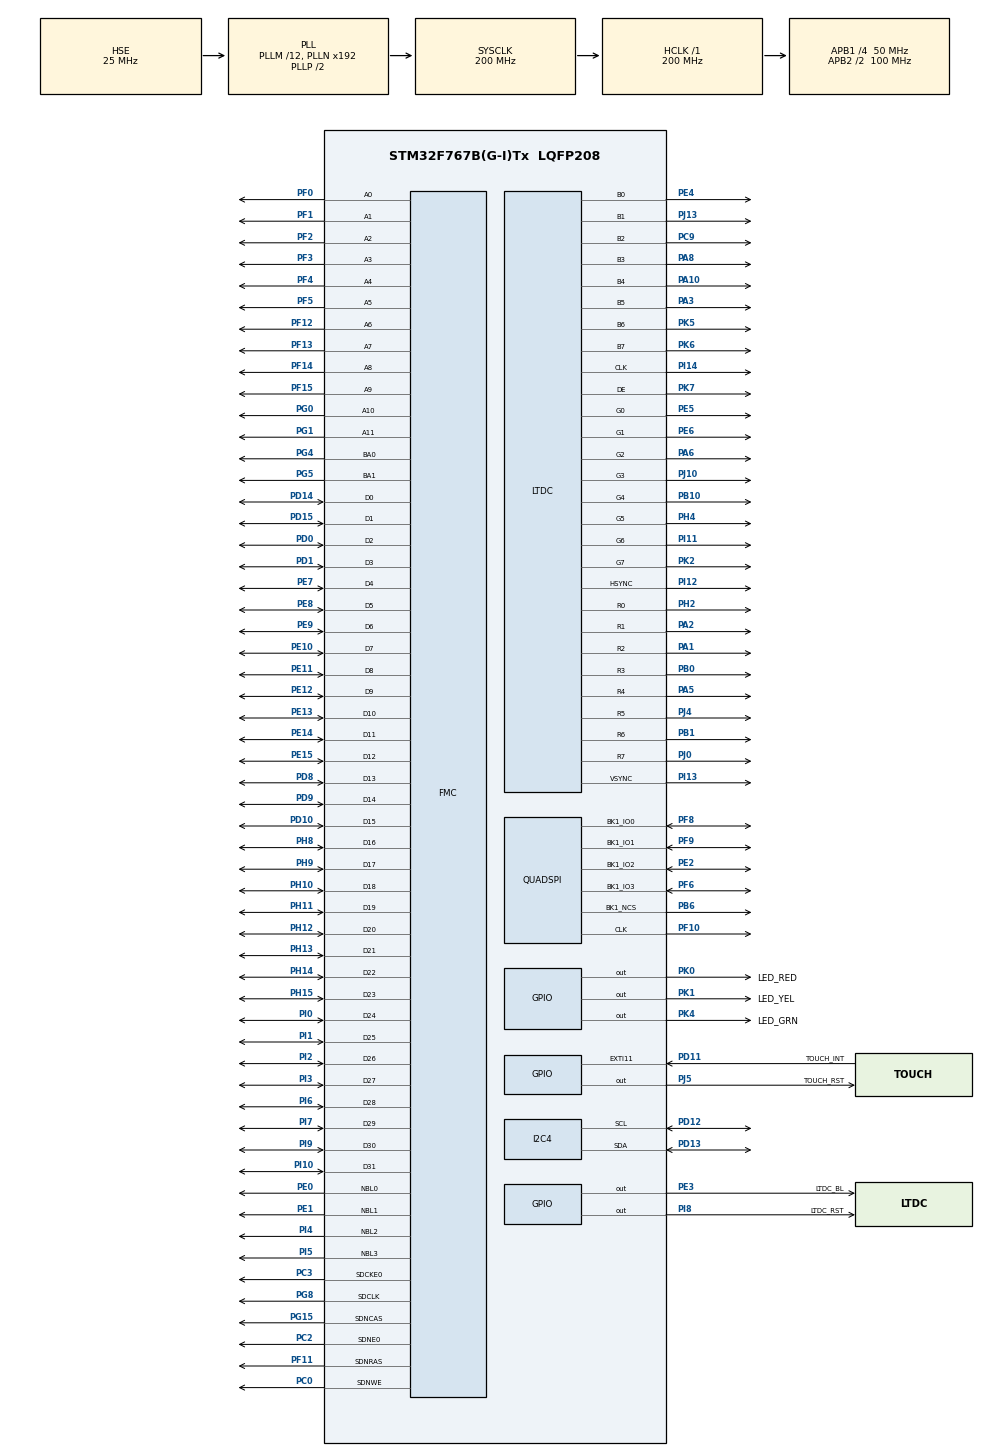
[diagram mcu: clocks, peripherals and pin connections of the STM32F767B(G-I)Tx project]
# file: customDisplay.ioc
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CORTEX_M7.ART_ACCELERATOR_ENABLE=1
DMA2D.ColorMode=DMA2D_OUTPUT_RGB888
FMC.CASLatency1=FMC_SDRAM_CAS_LATENCY_3
FMC.ColumnBitsNumber1=FMC_SDRAM_COLUMN_BITS_NUM_8
FMC.ExitSelfRefreshDelay1=7
FMC.LoadToActiveDelay1=2
FMC.RCDDelay1=3
FMC.RPDelay1=3
FMC.ReadBurst1=FMC_SDRAM_RBURST_ENABLE
FMC.RowCycleDelay1=10
FMC.SDClockPeriod1=FMC_SDRAM_CLOCK_PERIOD_2
FMC.SelfRefreshTime1=7
FMC.WriteRecoveryTime1=6
FREERTOS.Mutexes01=mutexLCD,Dynamic,NULL;mutexSDRAM,Dynamic,NULL;mutexFLASH,Dynamic,NULL;mutexTOUCH,Dynamic,NULL
FREERTOS.Tasks01=heartbeatTask,1,128,execHeartbeatTask,Default,NULL,Dynamic,NULL,NULL;lcdTestTask,-1,1024,execLcdTestTask,Default,NULL,Dynamic,NULL,NULL;sdramTestTask,-1,1024,execSdramTestTask,Default,NULL,Dynamic,NULL,NULL;flashTestTask,-1,1024,execFlashTestTask,Default,NULL,Dynamic,NULL,NULL;touchTestTask,-1,512,execTouchTestTask,Default,NULL,Dynamic,NULL,NULL;touchgfxTask,-2,8192,execTouchgfxTask,Default,NULL,Dynamic,NULL,NULL
FREERTOS.configGENERATE_RUN_TIME_STATS=1
FREERTOS.configTOTAL_HEAP_SIZE=65536
FREERTOS.configUSE_NEWLIB_REENTRANT=1
FREERTOS.configUSE_STATS_FORMATTING_FUNCTIONS=1
FREERTOS.configUSE_TRACE_FACILITY=1
I2C4.Timing=0x00C0EAFF
LTDC.ActiveH=272
LTDC.ActiveW=480
LTDC.Alpha_L0=255
LTDC.FBStartAdress_L0=0xC0000000
LTDC.HBP=43
LTDC.HFP=8
LTDC.HSync=1
LTDC.ImageHeight_L0=272
LTDC.ImageWidth_L0=480
LTDC.Layers=0
LTDC.PixelFormat_L0=LTDC_PIXEL_FORMAT_RGB888
LTDC.VBP=12
LTDC.VFP=4
LTDC.VSync=10
LTDC.WindowX1_L0=480
LTDC.WindowY1_L0=272
Mcu.Family=STM32F7
Mcu.Name=STM32F767B(G-I)Tx
Mcu.Package=LQFP208
NVIC.DMA2D_IRQn=true\:5\:0\:false\:false\:true\:true\:true\:true
NVIC.LTDC_IRQn=true\:5\:0\:false\:false\:true\:true\:true\:true
NVIC.PriorityGroup=NVIC_PRIORITYGROUP_4
NVIC.TIM8_TRG_COM_TIM14_IRQn=true\:15\:0\:false\:false\:true\:false\:false\:true
NVIC.TimeBase=TIM8_TRG_COM_TIM14_IRQn
NVIC.TimeBaseIP=TIM14
PA1.Mode=RGB888
PA1.Signal=LTDC_R2
PA10.Mode=RGB888
PA10.Signal=LTDC_B4
PA13.Mode=Trace_Asynchronous_SW
PA13.Signal=SYS_JTMS-SWDIO
PA14.Mode=Trace_Asynchronous_SW
PA14.Signal=SYS_JTCK-SWCLK
PA2.Mode=RGB888
PA2.Signal=LTDC_R1
PA3.Mode=RGB888
PA3.Signal=LTDC_B5
PA5.Mode=RGB888
PA5.Signal=LTDC_R4
PA6.Mode=RGB888
PA6.Signal=LTDC_G2
PA8.Mode=RGB888
PA8.Signal=LTDC_B3
PB0.Mode=RGB888
PB0.Signal=LTDC_R3
PB1.Mode=RGB888
PB1.Signal=LTDC_R6
PB10.Mode=RGB888
PB10.Signal=LTDC_G4
PB3.Mode=Trace_Asynchronous_SW
PB3.Signal=SYS_JTDO-SWO
PB6.Mode=Single Bank 1
PB6.Signal=QUADSPI_BK1_NCS
PC0.Signal=FMC_SDNWE
PC14/OSC32_IN.Mode=LSE-External-Oscillator
PC14/OSC32_IN.Signal=RCC_OSC32_IN
PC15/OSC32_OUT.Mode=LSE-External-Oscillator
PC15/OSC32_OUT.Signal=RCC_OSC32_OUT
PC2.Mode=SdramChipSelect1_1
PC2.Signal=FMC_SDNE0
PC3.Mode=SdramChipSelect1_1
PC3.Signal=FMC_SDCKE0
PC9.Mode=RGB888
PC9.Signal=LTDC_B2
PD0.Signal=FMC_D2_DA2
PD1.Signal=FMC_D3_DA3
PD10.Signal=FMC_D15_DA15
PD11.GPIO_Label=TOUCH_INT
PD11.Signal=GPXTI11
PD12.Mode=I2C
PD12.Signal=I2C4_SCL
PD13.Mode=I2C
PD13.Signal=I2C4_SDA
PD14.Signal=FMC_D0_DA0
PD15.Signal=FMC_D1_DA1
PD8.Signal=FMC_D13_DA13
PD9.Signal=FMC_D14_DA14
PE0.Signal=FMC_NBL0
PE1.Signal=FMC_NBL1
PE10.Signal=FMC_D7_DA7
PE11.Signal=FMC_D8_DA8
PE12.Signal=FMC_D9_DA9
PE13.Signal=FMC_D10_DA10
PE14.Signal=FMC_D11_DA11
PE15.Signal=FMC_D12_DA12
PE2.Mode=Single Bank 1
PE2.Signal=QUADSPI_BK1_IO2
PE3.GPIO_Label=LTDC_BL
PE3.Signal=GPIO_Output
PE4.Mode=RGB888
PE4.Signal=LTDC_B0
PE5.Mode=RGB888
PE5.Signal=LTDC_G0
PE6.Mode=RGB888
PE6.Signal=LTDC_G1
PE7.Signal=FMC_D4_DA4
PE8.Signal=FMC_D5_DA5
PE9.Signal=FMC_D6_DA6
PF0.Signal=FMC_A0
PF1.Signal=FMC_A1
PF10.Mode=Single Bank 1
PF10.Signal=QUADSPI_CLK
PF11.Signal=FMC_SDNRAS
PF12.Signal=FMC_A6
PF13.Signal=FMC_A7
PF14.Signal=FMC_A8
PF15.Signal=FMC_A9
PF2.Signal=FMC_A2
PF3.Signal=FMC_A3
PF4.Signal=FMC_A4
PF5.Signal=FMC_A5
PF6.Mode=Single Bank 1
PF6.Signal=QUADSPI_BK1_IO3
PF8.Mode=Single Bank 1
PF8.Signal=QUADSPI_BK1_IO0
PF9.Mode=Single Bank 1
PF9.Signal=QUADSPI_BK1_IO1
PG0.Signal=FMC_A10
PG1.Signal=FMC_A11
PG15.Signal=FMC_SDNCAS
PG2.Signal=FMC_A12
PG4.Signal=FMC_A14_BA0
PG5.Signal=FMC_A15_BA1
PG8.Signal=FMC_SDCLK
PH0/OSC_IN.Mode=HSE-External-Oscillator
PH0/OSC_IN.Signal=RCC_OSC_IN
PH1/OSC_OUT.Mode=HSE-External-Oscillator
PH1/OSC_OUT.Signal=RCC_OSC_OUT
PH10.Signal=FMC_D18
PH11.Signal=FMC_D19
PH12.Signal=FMC_D20
PH13.Signal=FMC_D21
PH14.Signal=FMC_D22
PH15.Signal=FMC_D23
PH2.Mode=RGB888
PH2.Signal=LTDC_R0
PH4.Mode=RGB888
PH4.Signal=LTDC_G5
PH8.Signal=FMC_D16
PH9.Signal=FMC_D17
PI0.Signal=FMC_D24
PI1.Signal=FMC_D25
PI10.Signal=FMC_D31
PI11.Mode=RGB888
PI11.Signal=LTDC_G6
PI12.Mode=RGB888
PI12.Signal=LTDC_HSYNC
PI13.Mode=RGB888
PI13.Signal=LTDC_VSYNC
PI14.Mode=RGB888
PI14.Signal=LTDC_CLK
PI2.Signal=FMC_D26
PI3.Signal=FMC_D27
PI4.Signal=FMC_NBL2
PI5.Signal=FMC_NBL3
PI6.Signal=FMC_D28
PI7.Signal=FMC_D29
PI8.GPIO_Label=LTDC_RST
PI8.Signal=GPIO_Output
PI9.Signal=FMC_D30
PJ0.Mode=RGB888
PJ0.Signal=LTDC_R7
PJ10.Mode=RGB888
PJ10.Signal=LTDC_G3
PJ13.Mode=RGB888
PJ13.Signal=LTDC_B1
PJ4.Mode=RGB888
PJ4.Signal=LTDC_R5
PJ5.GPIO_Label=TOUCH_RST
PJ5.Signal=GPIO_Output
PK0.GPIO_Label=LED_RED
PK0.Signal=GPIO_Output
PK1.GPIO_Label=LED_YEL
PK1.Signal=GPIO_Output
PK2.Mode=RGB888
PK2.Signal=LTDC_G7
PK4.GPIO_Label=LED_GRN
PK4.Signal=GPIO_Output
PK5.Mode=RGB888
PK5.Signal=LTDC_B6
PK6.Mode=RGB888
PK6.Signal=LTDC_B7
PK7.Mode=RGB888
PK7.Signal=LTDC_DE
ProjectManager.HeapSize=0x20000
ProjectManager.StackSize=0xF00
ProjectManager.TargetToolchain=STM32CubeIDE
QUADSPI.ClockPrescaler=1
QUADSPI.FifoThreshold=4
QUADSPI.FlashSize=25
RCC.AHBFreq_Value=200000000
RCC.APB1CLKDivider=RCC_HCLK_DIV4
RCC.APB1Freq_Value=50000000
RCC.APB1TimFreq_Value=100000000
RCC.APB2CLKDivider=RCC_HCLK_DIV2
RCC.APB2Freq_Value=100000000
RCC.APB2TimFreq_Value=200000000
RCC.CortexFreq_Value=200000000
RCC.HCLKFreq_Value=200000000
RCC.HSE_VALUE=25000000
RCC.HSI_VALUE=16000000
RCC.PLLM=12
RCC.PLLSAIR=5
RCC.PLLSAIRDiv=RCC_PLLSAIDIVR_8
RCC.PLLSourceVirtual=RCC_PLLSOURCE_HSE
RCC.SYSCLKFreq_VALUE=200000000
RCC.SYSCLKSource=RCC_SYSCLKSOURCE_PLLCLK
RCC.USBFreq_Value=200000000
RCC.VCOOutputFreq_Value=400000000
SH.FMC_A0.0=FMC_A0,12b-sda1
SH.FMC_A1.0=FMC_A1,12b-sda1
SH.FMC_A10.0=FMC_A10,12b-sda1
SH.FMC_A11.0=FMC_A11,12b-sda1
SH.FMC_A12.0=FMC_A12
SH.FMC_A14_BA0.0=FMC_BA0,FourSdramBanks1
SH.FMC_A15_BA1.0=FMC_BA1,FourSdramBanks1
SH.FMC_A2.0=FMC_A2,12b-sda1
SH.FMC_A3.0=FMC_A3,12b-sda1
SH.FMC_A4.0=FMC_A4,12b-sda1
SH.FMC_A5.0=FMC_A5,12b-sda1
SH.FMC_A6.0=FMC_A6,12b-sda1
SH.FMC_A7.0=FMC_A7,12b-sda1
SH.FMC_A8.0=FMC_A8,12b-sda1
SH.FMC_A9.0=FMC_A9,12b-sda1
SH.FMC_D0_DA0.0=FMC_D0,sd-32b-d1
SH.FMC_D10_DA10.0=FMC_D10,sd-32b-d1
SH.FMC_D11_DA11.0=FMC_D11,sd-32b-d1
SH.FMC_D12_DA12.0=FMC_D12,sd-32b-d1
SH.FMC_D13_DA13.0=FMC_D13,sd-32b-d1
SH.FMC_D14_DA14.0=FMC_D14,sd-32b-d1
SH.FMC_D15_DA15.0=FMC_D15,sd-32b-d1
SH.FMC_D16.0=FMC_D16,sd-32b-d1
SH.FMC_D17.0=FMC_D17,sd-32b-d1
SH.FMC_D18.0=FMC_D18,sd-32b-d1
SH.FMC_D19.0=FMC_D19,sd-32b-d1
SH.FMC_D1_DA1.0=FMC_D1,sd-32b-d1
SH.FMC_D20.0=FMC_D20,sd-32b-d1
SH.FMC_D21.0=FMC_D21,sd-32b-d1
SH.FMC_D22.0=FMC_D22,sd-32b-d1
SH.FMC_D23.0=FMC_D23,sd-32b-d1
SH.FMC_D24.0=FMC_D24,sd-32b-d1
SH.FMC_D25.0=FMC_D25,sd-32b-d1
SH.FMC_D26.0=FMC_D26,sd-32b-d1
SH.FMC_D27.0=FMC_D27,sd-32b-d1
SH.FMC_D28.0=FMC_D28,sd-32b-d1
SH.FMC_D29.0=FMC_D29,sd-32b-d1
SH.FMC_D2_DA2.0=FMC_D2,sd-32b-d1
SH.FMC_D30.0=FMC_D30,sd-32b-d1
SH.FMC_D31.0=FMC_D31,sd-32b-d1
SH.FMC_D3_DA3.0=FMC_D3,sd-32b-d1
SH.FMC_D4_DA4.0=FMC_D4,sd-32b-d1
SH.FMC_D5_DA5.0=FMC_D5,sd-32b-d1
SH.FMC_D6_DA6.0=FMC_D6,sd-32b-d1
SH.FMC_D7_DA7.0=FMC_D7,sd-32b-d1
SH.FMC_D8_DA8.0=FMC_D8,sd-32b-d1
SH.FMC_D9_DA9.0=FMC_D9,sd-32b-d1
SH.FMC_NBL0.0=FMC_NBL0,Sd4ByteEnable1
SH.FMC_NBL1.0=FMC_NBL1,Sd4ByteEnable1
SH.FMC_NBL2.0=FMC_NBL2,Sd4ByteEnable1
SH.FMC_NBL3.0=FMC_NBL3,Sd4ByteEnable1
SH.FMC_SDCLK.0=FMC_SDCLK,12b-sda1
SH.FMC_SDNCAS.0=FMC_SDNCAS,12b-sda1
SH.FMC_SDNRAS.0=FMC_SDNRAS,12b-sda1
SH.FMC_SDNWE.0=FMC_SDNWE,12b-sda1
VP_DMA2D_VS_DMA2D.Mode=DMA2D_Activate
VP_FREERTOS_VS_CMSIS_V1.Mode=CMSIS_V1
VP_SYS_VS_tim14.Mode=TIM14
board=custom

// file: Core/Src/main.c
/* USER CODE BEGIN Header */
/**
  ******************************************************************************
  * @file           : main.c
  * @brief          : Main program body
  ******************************************************************************
  * @attention
  *
  * Copyright (c) 2021 STMicroelectronics.
  * All rights reserved.
  *
  * This software is licensed under terms that can be found in the LICENSE file
  * in the root directory of this software component.
  * If no LICENSE file comes with this software, it is provided AS-IS.
  *
  ******************************************************************************
  */
/* USER CODE END Header */
#include "main.h"
#include "cmsis_os.h"
#include "dma2d.h"
#include "i2c.h"
#include "ltdc.h"
#include "quadspi.h"
#include "gpio.h"
#include "fmc.h"

/* USER CODE BEGIN Includes */
#include <stdio.h>
/* USER CODE END Includes */

void SystemClock_Config(void);
void MX_FREERTOS_Init(void);

int main(void)
{

  /* MCU Configuration--------------------------------------------------------*/

  /* Reset of all peripherals, Initializes the Flash interface and the Systick. */
  HAL_Init();

  /* Configure the system clock */
  SystemClock_Config();

  /* Initialize all configured peripherals */
  MX_GPIO_Init();
  MX_LTDC_Init();
  MX_FMC_Init();
  MX_QUADSPI_Init();
  MX_DMA2D_Init();
  MX_I2C4_Init();

  /* Call init function for freertos objects (in freertos.c) */
  MX_FREERTOS_Init();
  /* Start scheduler */
  osKernelStart();

  /* We should never get here as control is now taken by the scheduler */
  /* Infinite loop */
  while (1)
  {

  }
}

void SystemClock_Config(void)
{
  RCC_OscInitTypeDef RCC_OscInitStruct = {0};
  RCC_ClkInitTypeDef RCC_ClkInitStruct = {0};

  /** Configure LSE Drive Capability
  */
  HAL_PWR_EnableBkUpAccess();
  /** Configure the main internal regulator output voltage
  */
  __HAL_RCC_PWR_CLK_ENABLE();
  __HAL_PWR_VOLTAGESCALING_CONFIG(PWR_REGULATOR_VOLTAGE_SCALE1);
  /** Initializes the RCC Oscillators according to the specified parameters
  * in the RCC_OscInitTypeDef structure.
  */
  RCC_OscInitStruct.OscillatorType = RCC_OSCILLATORTYPE_HSE;
  RCC_OscInitStruct.HSEState = RCC_HSE_ON;
  RCC_OscInitStruct.PLL.PLLState = RCC_PLL_ON;
  RCC_OscInitStruct.PLL.PLLSource = RCC_PLLSOURCE_HSE;
  RCC_OscInitStruct.PLL.PLLM = 12;
  RCC_OscInitStruct.PLL.PLLN = 192;
  RCC_OscInitStruct.PLL.PLLP = RCC_PLLP_DIV2;
  RCC_OscInitStruct.PLL.PLLQ = 2;
  RCC_OscInitStruct.PLL.PLLR = 2;
  if (HAL_RCC_OscConfig(&RCC_OscInitStruct) != HAL_OK)
  {
    Error_Handler();
  }
  /** Activate the Over-Drive mode
  */
  if (HAL_PWREx_EnableOverDrive() != HAL_OK)
  {
    Error_Handler();
  }
  /** Initializes the CPU, AHB and APB buses clocks
  */
  RCC_ClkInitStruct.ClockType = RCC_CLOCKTYPE_HCLK|RCC_CLOCKTYPE_SYSCLK
                              |RCC_CLOCKTYPE_PCLK1|RCC_CLOCKTYPE_PCLK2;
  RCC_ClkInitStruct.SYSCLKSource = RCC_SYSCLKSOURCE_PLLCLK;
  RCC_ClkInitStruct.AHBCLKDivider = RCC_SYSCLK_DIV1;
  RCC_ClkInitStruct.APB1CLKDivider = RCC_HCLK_DIV4;
  RCC_ClkInitStruct.APB2CLKDivider = RCC_HCLK_DIV2;

  if (HAL_RCC_ClockConfig(&RCC_ClkInitStruct, FLASH_LATENCY_6) != HAL_OK)
  {
    Error_Handler();
  }
}

void HAL_TIM_PeriodElapsedCallback(TIM_HandleTypeDef *htim)
{
  if (htim->Instance == TIM14) {
    HAL_IncTick();
  }
}

void Error_Handler(void)
{
  __disable_irq();
  while (1)
  {
  }
}

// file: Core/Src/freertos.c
/* USER CODE BEGIN Header */
/**
  ******************************************************************************
  * File Name          : freertos.c
  * Description        : Code for freertos applications
  ******************************************************************************
  * @attention
  *
  * Copyright (c) 2021 STMicroelectronics.
  * All rights reserved.
  *
  * This software is licensed under terms that can be found in the LICENSE file
  * in the root directory of this software component.
  * If no LICENSE file comes with this software, it is provided AS-IS.
  *
  ******************************************************************************
  */
/* USER CODE END Header */

#include "FreeRTOS.h"
#include "task.h"
#include "main.h"
#include "cmsis_os.h"

/* USER CODE BEGIN Includes */
#include <stdio.h>
#include <stdlib.h>
#include <string.h>
#include "stm32f7xx_hal.h"
#include "ltdc.h"
#include "is42s32800g_conf.h"
#include "mt25ql512abb.h"
#include "quadspi.h"
#include "i2c.h"
/* USER CODE END Includes */

osThreadId heartbeatTaskHandle;
osThreadId lcdTestTaskHandle;
osThreadId sdramTestTaskHandle;
osThreadId flashTestTaskHandle;
osThreadId touchTestTaskHandle;
osThreadId touchgfxTaskHandle;
osMutexId mutexLCDHandle;
osMutexId mutexSDRAMHandle;
osMutexId mutexFLASHHandle;
osMutexId mutexTOUCHHandle;

void execHeartbeatTask(void const * argument);
void execLcdTestTask(void const * argument);
void execSdramTestTask(void const * argument);
void execFlashTestTask(void const * argument);
void execTouchTestTask(void const * argument);
void execTouchgfxTask(void const * argument);

void MX_FREERTOS_Init(void); /* (MISRA C 2004 rule 8.1) */

/* GetIdleTaskMemory prototype (linked to static allocation support) */
void vApplicationGetIdleTaskMemory( StaticTask_t **ppxIdleTaskTCBBuffer, StackType_t **ppxIdleTaskStackBuffer, uint32_t *pulIdleTaskStackSize );

/* Hook prototypes */
void configureTimerForRunTimeStats(void);
unsigned long getRunTimeCounterValue(void);

/* USER CODE BEGIN 1 */
/* Functions needed when configGENERATE_RUN_TIME_STATS is on */
__weak void configureTimerForRunTimeStats(void)
{

}

__weak unsigned long getRunTimeCounterValue(void)
{
  return HAL_GetTick();
}
/* USER CODE END 1 */

/* USER CODE BEGIN GET_IDLE_TASK_MEMORY */
static StaticTask_t xIdleTaskTCBBuffer;
static StackType_t xIdleStack[configMINIMAL_STACK_SIZE];

void vApplicationGetIdleTaskMemory( StaticTask_t **ppxIdleTaskTCBBuffer, StackType_t **ppxIdleTaskStackBuffer, uint32_t *pulIdleTaskStackSize )
{
  *ppxIdleTaskTCBBuffer = &xIdleTaskTCBBuffer;
  *ppxIdleTaskStackBuffer = &xIdleStack[0];
  *pulIdleTaskStackSize = configMINIMAL_STACK_SIZE;
  /* place for user code */
}
/* USER CODE END GET_IDLE_TASK_MEMORY */

void MX_FREERTOS_Init(void) {
  /* Create the mutex(es) */
  /* definition and creation of mutexLCD */
  osMutexDef(mutexLCD);
  mutexLCDHandle = osMutexCreate(osMutex(mutexLCD));

  /* definition and creation of mutexSDRAM */
  osMutexDef(mutexSDRAM);
  mutexSDRAMHandle = osMutexCreate(osMutex(mutexSDRAM));

  /* definition and creation of mutexFLASH */
  osMutexDef(mutexFLASH);
  mutexFLASHHandle = osMutexCreate(osMutex(mutexFLASH));

  /* definition and creation of mutexTOUCH */
  osMutexDef(mutexTOUCH);
  mutexTOUCHHandle = osMutexCreate(osMutex(mutexTOUCH));

  /* Create the thread(s) */
  /* definition and creation of heartbeatTask */
  osThreadDef(heartbeatTask, execHeartbeatTask, osPriorityAboveNormal, 0, 128);
  heartbeatTaskHandle = osThreadCreate(osThread(heartbeatTask), NULL);

  /* definition and creation of lcdTestTask */
  osThreadDef(lcdTestTask, execLcdTestTask, osPriorityBelowNormal, 0, 1024);
  lcdTestTaskHandle = osThreadCreate(osThread(lcdTestTask), NULL);

  /* definition and creation of sdramTestTask */
  osThreadDef(sdramTestTask, execSdramTestTask, osPriorityBelowNormal, 0, 1024);
  sdramTestTaskHandle = osThreadCreate(osThread(sdramTestTask), NULL);

  /* definition and creation of flashTestTask */
  osThreadDef(flashTestTask, execFlashTestTask, osPriorityBelowNormal, 0, 1024);
  flashTestTaskHandle = osThreadCreate(osThread(flashTestTask), NULL);

  /* definition and creation of touchTestTask */
  osThreadDef(touchTestTask, execTouchTestTask, osPriorityBelowNormal, 0, 512);
  touchTestTaskHandle = osThreadCreate(osThread(touchTestTask), NULL);

  /* definition and creation of touchgfxTask */
  osThreadDef(touchgfxTask, execTouchgfxTask, osPriorityLow, 0, 8192);
  touchgfxTaskHandle = osThreadCreate(osThread(touchgfxTask), NULL);

}

void execHeartbeatTask(void const * argument)
{
  /* USER CODE BEGIN execHeartbeatTask */
  printf("Starting heartbeatTask...\r\n");

  while(1)
  {
    HAL_GPIO_TogglePin(LED_GRN_GPIO_Port, LED_GRN_Pin);
    osDelay(500);
  }
  /* USER CODE END execHeartbeatTask */
}

void execLcdTestTask(void const * argument)
{
  /* USER CODE BEGIN execLcdTestTask */
  // Acquire LCD mutex
  while(osMutexWait(mutexLCDHandle, 0) != osOK)
  {
    osThreadYield();
  }

  printf("Starting lcdTestTask...\r\n");

  printf("Starting internal framebuffer test...\r\n");

  // Allocate framebuffer
  uint8_t *framebuffer = malloc(480*272*3);

  if(framebuffer == NULL)
  {
    printf("Could not allocate memory for framebuffer!\r\n");
    Error_Handler();
  }

  // Set LTDC framebuffer address
  if(HAL_LTDC_SetAddress(&hltdc, (uint32_t)framebuffer, LTDC_LAYER_1) != HAL_OK)
  {
    printf("Error setting framebuffer address!\r\n");
    Error_Handler();
  }

  // Turn on display
  HAL_GPIO_WritePin(LTDC_BL_GPIO_Port, LTDC_BL_Pin, GPIO_PIN_SET);
  HAL_GPIO_WritePin(LTDC_RST_GPIO_Port, LTDC_RST_Pin, GPIO_PIN_SET);

  // Write red to the display
  uint8_t *fb = framebuffer;

  while(fb < (uint8_t *)(framebuffer + (480*272*3)))
  {
    *fb++ = 0x00;   // Blue
    *fb++ = 0x00;   // Green
    *fb++ = 0xFF;   // Red
  }

  osDelay(1000);

  // Write green to the display
  fb = framebuffer;

  while(fb < (uint8_t *)(framebuffer + (480*272*3)))
  {
    *fb++ = 0x00;   // Blue
    *fb++ = 0xFF;   // Green
    *fb++ = 0x00;   // Red
  }

  osDelay(1000);

  // Write blue to the display
  fb = framebuffer;

  while(fb < (uint8_t *)(framebuffer + (480*272*3)))
  {
    *fb++ = 0xFF;   // Blue
    *fb++ = 0x00;   // Green
    *fb++ = 0x00;   // Red
  }

  osDelay(1000);

  // Write white to the display
  fb = framebuffer;

  while(fb < (uint8_t *)(framebuffer + (480*272*3)))
  {
    *fb++ = 0xFF;   // Blue
    *fb++ = 0xFF;   // Green
    *fb++ = 0xFF;   // Red
  }

  osDelay(1000);

  // Turn off display
  HAL_GPIO_WritePin(LTDC_BL_GPIO_Port, LTDC_BL_Pin, GPIO_PIN_RESET);
  HAL_GPIO_WritePin(LTDC_RST_GPIO_Port, LTDC_RST_Pin, GPIO_PIN_RESET);

  printf("Ending lcdTestTask...\r\n");

  free(framebuffer);
  osMutexRelease(mutexLCDHandle);
  osThreadTerminate(lcdTestTaskHandle);
  /* USER CODE END execLcdTestTask */
}

void execSdramTestTask(void const * argument)
{
  /* USER CODE BEGIN execSdramTestTask */
  volatile uint32_t *externalRAM = (uint32_t *)IS42S32800G_ADDRESS;
  const uint32_t sizeRAM = IS42S32800G_SIZE;
  uint32_t i = 0;
  int32_t before, after;
  float elapsed;

  // Acquire SDRAM mutex
  while(osMutexWait(mutexSDRAMHandle, 0) != osOK)
  {
    osThreadYield();
  }

  printf("Starting sdramTestTask...\r\n");

  // Write Test
  before = HAL_GetTick();
  while(i < (sizeRAM/4))
  {
      *(externalRAM + i) = i;
      i++;
  }
  after = HAL_GetTick();

  elapsed = ((after - before) / 1000.0);

  printf("RAM - Wrote %ld words in %3.2f seconds (%3.2fMBs)\n",
          i, elapsed, ((((i * 4) / 1024) / 1024) / elapsed) );

  // Read Test
  i = 0;

  before = HAL_GetTick();
  while(i < (sizeRAM/4))
  {
      if(*(externalRAM + i) != i)
      {
          break;
      }
      else
      {
          i++;
      }
  }
  after = HAL_GetTick();

  elapsed = ((after - before) / 1000.0);

  printf("RAM - Read %ld words in %3.2f seconds (%3.2fMBs)\n",
          i, elapsed, ((((i * 4) / 1024) / 1024) / elapsed) );

  // Framebuffer in external SDRAM

  // Acquire LCD mutex
  while(osMutexWait(mutexLCDHandle, 0) != osOK)
  {
    osThreadYield();
  }

  printf("Starting external framebuffer test...\r\n");

  uint8_t *framebuffer = (uint8_t *)0xC0000000;

  if(HAL_LTDC_SetAddress(&hltdc, (uint32_t)framebuffer, LTDC_LAYER_1) != HAL_OK)
  {
    printf("Error changing LTDC framebuffer address!");
    Error_Handler();
  }

  // Turn on display
  HAL_GPIO_WritePin(LTDC_BL_GPIO_Port, LTDC_BL_Pin, GPIO_PIN_SET);
  HAL_GPIO_WritePin(LTDC_RST_GPIO_Port, LTDC_RST_Pin, GPIO_PIN_SET);

  // Write red to the display
  uint8_t *fb = framebuffer;

  while(fb < (uint8_t *)(framebuffer + (480*272*3)))
  {
    *fb++ = 0x00;   // Blue
    *fb++ = 0x00;   // Green
    *fb++ = 0xFF;   // Red
  }

  osDelay(1000);

  // Write green to the display
  fb = framebuffer;

  while(fb < (uint8_t *)(framebuffer + (480*272*3)))
  {
    *fb++ = 0x00;   // Blue
    *fb++ = 0xFF;   // Green
    *fb++ = 0x00;   // Red
  }

  osDelay(1000);

  // Write blue to the display
  fb = framebuffer;

  while(fb < (uint8_t *)(framebuffer + (480*272*3)))
  {
    *fb++ = 0xFF;   // Blue
    *fb++ = 0x00;   // Green
    *fb++ = 0x00;   // Red
  }

  osDelay(1000);

  // Write white to the display
  fb = framebuffer;

  while(fb < (uint8_t *)(framebuffer + (480*272*3)))
  {
    *fb++ = 0xFF;   // Blue
    *fb++ = 0xFF;   // Green
    *fb++ = 0xFF;   // Red
  }

  osDelay(1000);

  // Turn off display
  HAL_GPIO_WritePin(LTDC_BL_GPIO_Port, LTDC_BL_Pin, GPIO_PIN_RESET);
  HAL_GPIO_WritePin(LTDC_RST_GPIO_Port, LTDC_RST_Pin, GPIO_PIN_RESET);

  printf("Ending sdramTestTask...\r\n");
  osMutexRelease(mutexLCDHandle);
  osMutexRelease(mutexSDRAMHandle);
  osThreadTerminate(sdramTestTaskHandle);
  /* USER CODE END execSdramTestTask */
}

void execFlashTestTask(void const * argument)
{
  /* USER CODE BEGIN execFlashTestTask */
  while(osMutexWait(mutexFLASHHandle, 0) != osOK)
  {
    osThreadYield();
  }

  printf("Starting flashTestTask...\r\n");

  uint32_t var;
  int32_t before, after;
  float elapsed;
  uint8_t *buffer_test;

  // Create test data
  do
  {
    buffer_test = malloc((size_t)MT25QL512ABB_SECTOR_64K);

    if(buffer_test == NULL)
    {
      osDelay(10);
    }
  }
  while(buffer_test == NULL);

  for (var = 0; var < MT25QL512ABB_SECTOR_64K; var++)
  {
    buffer_test[var] = (var & 0xff);
  }

  // Exit memory mapped mode
  if(HAL_QSPI_Abort(&hqspi) != HAL_OK)
  {
    Error_Handler();
  }

  // Erase Sector
  before = HAL_GetTick();
  if(MT25QL512ABB_BlockErase(&hqspi,
                                MT25QL512ABB_QPI_MODE,
                                MT25QL512ABB_4BYTES_SIZE,
                                1023 * MT25QL512ABB_SECTOR_64K,
                                MT25QL512ABB_ERASE_64K)
      != MT25QL512ABB_OK)
  {
    Error_Handler();
  }

  // Poll WIP
  if(MT25QL512ABB_AutoPollingMemReady(&hqspi,
                                        MT25QL512ABB_QPI_MODE,
                                        MT25QL512ABB_DUALFLASH_DISABLE)
      != MT25QL512ABB_OK)
  {
    Error_Handler();
  }

  // Write test data
  for(int i = 0; i < MT25QL512ABB_SECTOR_64K /  MT25QL512ABB_PAGE_SIZE; i++)
  {
    // Set WIP
    if(MT25QL512ABB_WriteEnable(&hqspi,
                                  MT25QL512ABB_QPI_MODE,
                                  MT25QL512ABB_DUALFLASH_DISABLE)
        != MT25QL512ABB_OK)

    {
      Error_Handler();
    }
    // Program page
    if(MT25QL512ABB_PageProgram(&hqspi,
                                  MT25QL512ABB_QPI_MODE,
                                  MT25QL512ABB_4BYTES_SIZE,
                                  (buffer_test + (MT25QL512ABB_PAGE_SIZE * i)),
                                  ((1023 * MT25QL512ABB_SECTOR_64K) + (MT25QL512ABB_PAGE_SIZE * i)),
                                  MT25QL512ABB_PAGE_SIZE)
        != MT25QL512ABB_OK)
    {
      Error_Handler();
    }
    // Poll WIP
    if(MT25QL512ABB_AutoPollingMemReady(&hqspi,
                                          MT25QL512ABB_QPI_MODE,
                                          MT25QL512ABB_DUALFLASH_DISABLE)
        != MT25QL512ABB_OK)
    {
      Error_Handler();
    }
  }
  after = HAL_GetTick();

  elapsed = ((after - before) / 1000.0);

  printf("FLASH - Wrote %ld bytes in %3.2f seconds (%3.2fKBs)\n",
      (uint32_t)MT25QL512ABB_SECTOR_64K, elapsed, (float)(((MT25QL512ABB_SECTOR_64K) / 1024) / elapsed) );

  // Put back into memory mapped mode
  if(MT25QL512ABB_EnableMemoryMappedModeSTR(&hqspi,
      MT25QL512ABB_QPI_MODE,
      MT25QL512ABB_4BYTES_SIZE)
  != MT25QL512ABB_OK)
  {
    Error_Handler();
  }

  // Check that written data matches
  before = HAL_GetTick();
  if(memcmp(buffer_test, (uint8_t *)(0x90000000 + (1023 * MT25QL512ABB_SECTOR_64K)), MT25QL512ABB_SECTOR_64K))
  {
    Error_Handler();
  }
  after = HAL_GetTick();

  elapsed = ((after - before) / 1000.0);

  printf("FLASH - Read %ld bytes in %3.2f seconds (%3.2fKBs)\n",
        (uint32_t)MT25QL512ABB_SECTOR_64K, elapsed, (float)(((MT25QL512ABB_SECTOR_64K) / 1024) / elapsed) );

  printf("Ending flashTestTask...\r\n");
  free(buffer_test);
  osMutexRelease(mutexFLASHHandle);
  osThreadTerminate(flashTestTaskHandle);
  /* USER CODE END execFlashTestTask */
}

void execTouchTestTask(void const * argument)
{
  /* USER CODE BEGIN execTouchTestTask */
  while(osMutexWait(mutexTOUCHHandle, 0) != osOK)
  {
    osThreadYield();
  }

  printf("Starting touchTestTask...\r\n");

  printf("Ending touchTestTask...\r\n");
  osMutexRelease(mutexTOUCHHandle);
  osThreadTerminate(touchTestTaskHandle);
  /* USER CODE END execTouchTestTask */
}

void execTouchgfxTask(void const * argument)
{
  for(;;)
  {
    osDelay(1);
  }
}
